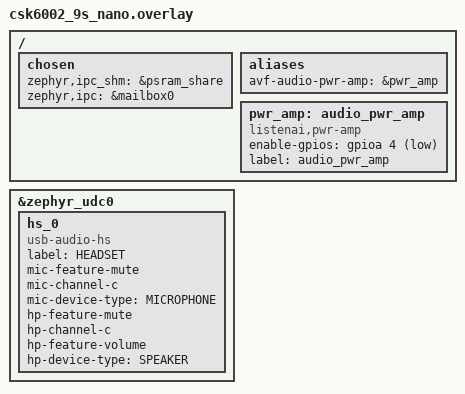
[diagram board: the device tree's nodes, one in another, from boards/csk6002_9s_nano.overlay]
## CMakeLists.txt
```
# SPDX-License-Identifier: Apache-2.0

cmake_minimum_required(VERSION 3.20.0)

set(SUPPORT_BOARDS csk6012_nano csk6011a_nano)
if(NOT ${BOARD} IN_LIST SUPPORT_BOARDS)
    message("Please choose one of the following boards:")
    foreach(item ${SUPPORT_BOARDS})
        message(STATUS ${item})
    endforeach()
    message(FATAL_ERROR "\nThe project does not support the ${BOARD}")
endif()

set(CONF_FILE
  prj.conf
)

if(EXISTS "${CMAKE_CURRENT_SOURCE_DIR}/boards/${BOARD}.conf")
  list(APPEND CONF_FILE
    ${CMAKE_CURRENT_SOURCE_DIR}/boards/${BOARD}.conf
  )
endif()

if(EXISTS "${CMAKE_CURRENT_SOURCE_DIR}/resource/res.conf")
  list(APPEND CONF_FILE
    ${CMAKE_CURRENT_SOURCE_DIR}/resource/res.conf
  )
endif()

set(DTC_OVERLAY_FILE)

if(EXISTS "${CMAKE_CURRENT_SOURCE_DIR}/boards/${BOARD}.overlay")
  list(APPEND DTC_OVERLAY_FILE
    ${CMAKE_CURRENT_SOURCE_DIR}/boards/${BOARD}.overlay
  )
endif()

if(EXISTS "${CMAKE_CURRENT_SOURCE_DIR}/resource/res.overlay")
  list(APPEND DTC_OVERLAY_FILE
    ${CMAKE_CURRENT_SOURCE_DIR}/resource/res.overlay
  )
endif()

find_package(Zephyr REQUIRED HINTS $ENV{ZEPHYR_BASE})
project(aplay_by_uac)
target_sources(app PRIVATE src/main.c)
```

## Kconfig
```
# SPDX-License-Identifier: Apache-2.0

DT_CHOSEN_Z_IPC_SHM := zephyr,ipc_shm

#SOF IPC MEMORY CONFIG
config SOF_IPC_SHM_BASE_ADDRESS
	default "$(dt_chosen_reg_addr_hex,$(DT_CHOSEN_Z_IPC_SHM))"

config SOF_IPC_SHM_SIZE
	default "$(dt_chosen_reg_size_hex,$(DT_CHOSEN_Z_IPC_SHM))"
	help
	  This option specifies size of the memory region to be used
	  for the SOF IPC shared memory

source "Kconfig.zephyr"
```

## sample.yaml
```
sample:
  name: USB audio headset sample
tests:
  sample.board.csk6.subsys.usb.audio.aplay_by_uac:
    depends_on: usb_device
    tags: usb
    build_only: true
    platform_allow: csk6011a_nano
    harness: console
    harness_config:
      type: multi_line
      ordered: true
      regex:
        - "Found USB Headset Device"
        - "USB enabled"
        - "Trigger play start success"
```

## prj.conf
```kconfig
CONFIG_STDOUT_CONSOLE=y

#USB related configs
CONFIG_USB_DEVICE_STACK=y
CONFIG_USB_DEVICE_PRODUCT="Zephyr USB audio sample"

#LOG subsystem related configs
CONFIG_LOG=y
CONFIG_LOG_MODE_DEFERRED=y
# CONFIG_LOG_BUFFER_SIZE=20480
# CONFIG_USB_DRIVER_LOG_LEVEL_ERR=y

#Ring buffer
CONFIG_RING_BUFFER=y

#net buf options
CONFIG_NET_BUF=y
CONFIG_NET_BUF_USER_DATA_SIZE=0

#USB audio related configs
CONFIG_USB_DEVICE_AUDIO=y

CONFIG_USB_DEVICE_VID=0x3421
CONFIG_USB_DEVICE_PID=0x0109
CONFIG_USB_DEVICE_MANUFACTURER="ListenAI"
CONFIG_USB_DEVICE_PRODUCT="ListenAi USB audio"
CONFIG_USB_DEVICE_SN="0123456789ABCDB1"

CONFIG_MAIN_STACK_SIZE=2048

#system heap size,users can define it according to the actual usage
CONFIG_HEAP_MEM_POOL_SIZE=92160

#avf
CONFIG_AVF=y
CONFIG_AVF_DEBUG_LEVEL=1
CONFIG_AVF_USE_BINARY_ARRAY=y

#licak
CONFIG_LICAK=y
CONFIG_LICAK_MODULES_AUDIO_PLAYBACK=y
CONFIG_LICAK_DISABLE_MULTI_HEAP_INIT=y

#IPM and GPIO for avf driver
CONFIG_IPM=y
CONFIG_GPIO=y

#cache
CONFIG_CACHE_MANAGEMENT=y
# CONFIG_USB_AUDIO_LOG_LEVEL_DBG=y
```

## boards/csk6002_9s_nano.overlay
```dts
/*
 * SPDX-License-Identifier: Apache-2.0
 */
#define MICROPHONE    0x0201
#define DESKTOP_MIC   0x0202
#define PERSONAL_MIC  0x0203

#define SPEAKER        0x0301
#define HEADPHONES     0x0302
#define HEAD_AUDIO     0x0303

&zephyr_udc0 {
	hs_0 {
		label = "HEADSET";
		compatible = "usb-audio-hs";
		mic-feature-mute;
		mic-channel-c;
		mic-device-type = <MICROPHONE>;

		hp-feature-mute;
		hp-channel-c;
		hp-feature-volume;
		hp-device-type = <SPEAKER>;
	};
};


 / {
	 chosen {
		 /*
		  * shared memory reserved for the inter-processor communication
		  */
		 zephyr,ipc_shm = &psram_share;
		 zephyr,ipc = &mailbox0;
	 };
 
	 aliases {
		 avf-audio-pwr-amp = &pwr_amp;
	 };
	 pwr_amp:audio_pwr_amp{
		 compatible = "listenai,pwr-amp";
		 enable-gpios = <&gpioa 4 1>;
		 label = "audio_pwr_amp";	
		 status = "okay";
	 };
 
 };
 
 
 
```

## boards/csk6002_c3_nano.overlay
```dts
/*
 * SPDX-License-Identifier: Apache-2.0
 */

#define MICROPHONE    0x0201
#define DESKTOP_MIC   0x0202
#define PERSONAL_MIC  0x0203

#define SPEAKER        0x0301
#define HEADPHONES     0x0302
#define HEAD_AUDIO     0x0303

&zephyr_udc0 {
	hs_0 {
		label = "HEADSET";
		compatible = "usb-audio-hs";
		mic-feature-mute;
		mic-channel-c;
		mic-device-type = <MICROPHONE>;

		hp-feature-mute;
		hp-channel-c;
		hp-feature-volume;
		hp-device-type = <SPEAKER>;
	};
};

 / {
	 chosen {
		 /*
		  * shared memory reserved for the inter-processor communication
		  */
		 zephyr,ipc_shm = &psram_share;
		 zephyr,ipc = &mailbox0;
	 };
 
	 aliases {
		 avf-audio-pwr-amp = &pwr_amp;
	 };
	 pwr_amp:audio_pwr_amp{
		 compatible = "listenai,pwr-amp";
		 enable-gpios = <&gpioa 4 1>;
		 label = "audio_pwr_amp";	
		 status = "okay";
	 };
 
 };
 
 
```

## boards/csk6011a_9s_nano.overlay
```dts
/*
 * SPDX-License-Identifier: Apache-2.0
 */


#define MICROPHONE    0x0201
#define DESKTOP_MIC   0x0202
#define PERSONAL_MIC  0x0203

#define SPEAKER        0x0301
#define HEADPHONES     0x0302
#define HEAD_AUDIO     0x0303

&zephyr_udc0 {
	hs_0 {
		label = "HEADSET";
		compatible = "usb-audio-hs";
		mic-feature-mute;
		mic-channel-c;
		mic-device-type = <MICROPHONE>;

		hp-feature-mute;
		hp-channel-c;
		hp-feature-volume;
		hp-device-type = <SPEAKER>;
	};
};

 / {
	 chosen {
		 /*
		  * shared memory reserved for the inter-processor communication
		  */
		 zephyr,ipc_shm = &psram_share;
		 zephyr,ipc = &mailbox0;
	 };
 
	 aliases {
		 avf-audio-pwr-amp = &pwr_amp;
	 };
	 pwr_amp:audio_pwr_amp{
		 compatible = "listenai,pwr-amp";
		 enable-gpios = <&gpioa 4 1>;
		 label = "audio_pwr_amp";	
		 status = "okay";
	 };
 
 };
 
 
```

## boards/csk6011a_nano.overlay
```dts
/*
 * Copyright (c) 2023 Anhui(Shenzhen) Listenai Co., Ltd.
 *
 * SPDX-License-Identifier: Apache-2.0
 */
#define MICROPHONE    0x0201
#define DESKTOP_MIC   0x0202
#define PERSONAL_MIC  0x0203

#define SPEAKER        0x0301
#define HEADPHONES     0x0302
#define HEAD_AUDIO     0x0303

&zephyr_udc0 {
	hs_0 {
		label = "HEADSET";
		compatible = "usb-audio-hs";
		mic-feature-mute;
		mic-channel-c;
		mic-device-type = <MICROPHONE>;

		hp-feature-mute;
		hp-channel-c;
		hp-feature-volume;
		hp-device-type = <SPEAKER>;
	};
};


/ {
	chosen {
		/*
		 * shared memory reserved for the inter-processor communication
		 */
		zephyr,ipc_shm = &psram_share;
		zephyr,ipc = &mailbox0;
	};

	aliases {
		avf-audio-pwr-amp = &pwr_amp;
	};
	pwr_amp: audio_pwr_amp{
		compatible = "listenai,pwr-amp";
		enable-gpios = <&gpioa 4 1>;
		label = "audio_pwr_amp";
		status = "okay";
	};

};
```

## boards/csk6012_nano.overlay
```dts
/*
 * Copyright (c) 2023 Anhui(Shenzhen) Listenai Co., Ltd.
 *
 * SPDX-License-Identifier: Apache-2.0
 */
#define MICROPHONE    0x0201
#define DESKTOP_MIC   0x0202
#define PERSONAL_MIC  0x0203

#define SPEAKER        0x0301
#define HEADPHONES     0x0302
#define HEAD_AUDIO     0x0303

&zephyr_udc0 {
	hs_0 {
		label = "HEADSET";
		compatible = "usb-audio-hs";
		mic-feature-mute;
		mic-channel-c;
		mic-device-type = <MICROPHONE>;

		hp-feature-mute;
		hp-channel-c;
		hp-feature-volume;
		hp-device-type = <SPEAKER>;
	};
};

/ {
	chosen {
		/*
		 * shared memory reserved for the inter-processor communication
		 */
		zephyr,ipc_shm = &psram_share;
		zephyr,ipc = &mailbox0;
	};

};
```

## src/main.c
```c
/*
 * Copyright (c) 2023 Anhui(Shenzhen) Listenai Co., Ltd.
 *
 * @brief Sample app for Aplay by USB Audio
 *
 * SPDX-License-Identifier: Apache-2.0
 */

#include "kernel.h"
#include "logging/log.h"
#include <stdint.h>
#include <string.h>
#include <zephyr.h>
#include <sys/ring_buffer.h>
#include <usb/usb_device.h>
#include <usb/class/usb_audio.h>
#include <avf/framework/avf_platform.h>
#include <licak/modules/audio/aplay.h>
#include <licak/licak.h>
#include <avf/slogger.h>
#include "pwr_amp.c"
#define PERIOD_BYTES(fmt) amedia_frames_to_bytes(fmt, 1000)

#define ID_RIFF 0x46464952
#define ID_WAVE 0x45564157
#define ID_FMT 0x20746d66
#define ID_DATA 0x61746164

#define UAC_BUF_SIZE (96 * 1000)

#define UAC_BUF_CACHE_SIZE (96 * 5)

#define UAC_BUF_TIMEOUT (K_MSEC(5))	//ms

#define UAC_BUF_TYPE 1

#define PRIORITY 6

#define UAC_BIT_DEPTH 16
#define UAC_SAMPLE_RATE 48000
#define UAC_CHANNEL_SUM 1

struct riff_wave_header {
	uint32_t riff_id;
	uint32_t riff_sz;
	uint32_t wave_id;
};

struct chunk_header {
	uint32_t id;
	uint32_t sz;
};

struct chunk_fmt {
	uint16_t audio_format;
	uint16_t num_channels;
	uint32_t sample_rate;
	uint32_t byte_rate;
	uint16_t block_align;
	uint16_t bits_per_sample;
};

static aplay_t *aplay = NULL;

K_SEM_DEFINE(uac_sem, 0, 1);
RING_BUF_DECLARE(uac_buf, UAC_BUF_SIZE);

K_THREAD_STACK_DEFINE(thread_uac_stack_area, 1024);
static struct k_thread thread_uac;

static void timer_expiry_cb(struct k_timer *timer);
K_TIMER_DEFINE(uac_timer, timer_expiry_cb, NULL);


static void timer_expiry_cb(struct k_timer *timer)
{
	k_sem_give(&uac_sem);
}

static void put_in_buf(uint8_t *data, size_t size)
{
	int ret;
	uint8_t *buf_data = NULL;
	uint32_t buf_size = 0;
	buf_size = ring_buf_put_claim(&uac_buf, &buf_data, size);
	if (buf_size != size) {
		LOG_ERR("actual claimed size: %d, request size: %d", buf_size, size);
	}
	memcpy(buf_data, data, buf_size);

	ret = ring_buf_put_finish(&uac_buf, buf_size);
	if (ret != 0) {
		LOG_ERR("ring_buf_put_finish ret: %d", ret);
	}

}

static void uac_notify(void)
{
	int used_size = ring_buf_size_get(&uac_buf);
	/* Cache some data then use aplay to play */
	if (used_size >= UAC_BUF_CACHE_SIZE) {
		k_sem_give(&uac_sem);
		k_timer_stop(&uac_timer);
	} else {
		/* Make sure left data in buffer could be consumed */
		k_timer_start(&uac_timer, UAC_BUF_TIMEOUT, K_NO_WAIT);
	}
}

static void get_from_buf(uint8_t **out_data_addr, size_t *out_size)
{
	*out_size = ring_buf_get_claim(&uac_buf, out_data_addr, UAC_BUF_SIZE);
}

static void finish_get_from_buf(size_t size)
{
	int ret;
	ret = ring_buf_get_finish(&uac_buf, size);
	if (ret != 0) {
		LOG_ERR("ring_buf_get_finish ret: %d", ret);
	}
}

static void play_audio(uint8_t *data, size_t size)
{
	int iret;
	iret = aplay_writei(aplay, (char *)data, size);
	if (iret != size) {
		LOG_ERR("### aplay_writei error ret %d, size %d ####", iret, size);
		return;
	}
}

void thread_uac_entry(void *dummy1, void *dummy2, void *dummy3)
{
	ARG_UNUSED(dummy1);
	ARG_UNUSED(dummy2);
	ARG_UNUSED(dummy3);

	uint8_t *data = NULL;
	size_t size = 0;

	while (true) {
		k_sem_take(&uac_sem, K_FOREVER);
		get_from_buf(&data, &size);
		play_audio(data, size);
		finish_get_from_buf(size);
	}
}

static void init_uac_thread(void)
{
	k_thread_create(&thread_uac, thread_uac_stack_area,
			K_THREAD_STACK_SIZEOF(thread_uac_stack_area), thread_uac_entry, NULL, NULL,
			NULL, PRIORITY, 0, K_NO_WAIT);
}


static void init_sof(void)
{
	int iret;
	amedia_fmt_t fmt;

	licak_init();
	memset(&fmt, 0, sizeof(amedia_fmt_t));

	fmt.channels = UAC_CHANNEL_SUM;
	fmt.rate = UAC_SAMPLE_RATE;
	fmt.compr = AMEDIA_COMPR_PCM;
	fmt.bits = UAC_BIT_DEPTH;

	printk("Prepare start play wav and get audio fmt <PCM/%d/%d /%d>\n", fmt.rate, fmt.channels,
	       fmt.bits);
	/*step1: create aplyer instance*/
	aplay = aplay_create(APLAYER_SUBSTREAM_MAIN);
	if (aplay == NULL) {
		printk("acap_create failed!\n");
		return;
	}
	printk("Create aplay success\n");

	/*step2: set aplayer paramter*/
	if (0 != (iret = aplay_set_fmt(aplay, &fmt))) {
		printk("aplay_set_fmt failed!\n");
		return;
	}
	printk("Set audio fmt to aplay success\n");

	/*Enable audio power-amp*/
	audio_pwr_amp_init();
    audio_pwr_amp_enbale();

	/*step3: start play*/
	if (0 != (iret = aplay_start(aplay))) {
		printk("aplay_set_fmt failed.\n");
		return;
	}
	printk("Trigger play start success.\n");

}

static void data_received(const struct device *dev, struct net_buf *buffer, size_t size)
{
	if (!buffer || !size) {
		/* This should never happen */
		return;
	}

	put_in_buf(buffer->data, size);
	net_buf_unref(buffer);
	uac_notify();
}

static void feature_update(const struct device *dev, const struct usb_audio_fu_evt *evt)
{
	LOG_DBG("Control selector %d for channel %d updated", (uint8_t)evt->cs, evt->channel);
	switch (evt->cs) {
	case USB_AUDIO_FU_MUTE_CONTROL:
		break;
	case USB_AUDIO_FU_VOLUME_CONTROL:
		LOG_DBG("[%s] volume: %d, val_len: %d", __FUNCTION__, *((int16_t *)(evt->val)),
			evt->val_len);
		break;
	default:
		break;
	}
}

static const struct usb_audio_ops ops = {
	.data_received_cb = data_received,
	.feature_update_cb = feature_update,
};

void main(void)
{
	const struct device *hs_dev;
	int ret;

	hs_dev = device_get_binding("HEADSET");

	if (!hs_dev) {
		printk("Can not get USB Headset Device \n");
		return;
	}

	printk("Found USB Headset Device \n");

	usb_audio_register(hs_dev, &ops);

	ret = usb_enable(NULL);
	if (ret != 0) {
		printk("Failed to enable USB \n");
		return;
	}

	printk("USB enabled \n");

	init_sof();
	init_uac_thread();
}
```

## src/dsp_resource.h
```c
/*
 * SPDX-License-Identifier: Apache-2.0
 */



static const unsigned char dsp_firmware[] = {
#include "dsp_firmware.inc"
};

static const unsigned char dsp_tplg[] = {
#include "dsp_tplg.inc"
};
```
